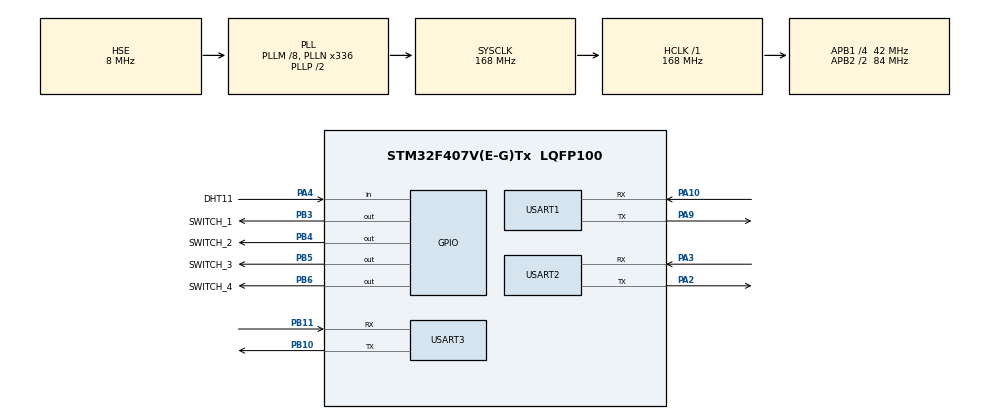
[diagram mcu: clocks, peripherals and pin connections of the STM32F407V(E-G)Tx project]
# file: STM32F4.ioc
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Dma.Request0=USART3_RX
Dma.Request1=USART3_TX
Dma.USART3_RX.0.Direction=DMA_PERIPH_TO_MEMORY
Dma.USART3_RX.0.FIFOMode=DMA_FIFOMODE_DISABLE
Dma.USART3_RX.0.Instance=DMA1_Stream1
Dma.USART3_RX.0.MemDataAlignment=DMA_MDATAALIGN_BYTE
Dma.USART3_RX.0.MemInc=DMA_MINC_ENABLE
Dma.USART3_RX.0.Mode=DMA_CIRCULAR
Dma.USART3_RX.0.PeriphDataAlignment=DMA_PDATAALIGN_BYTE
Dma.USART3_RX.0.PeriphInc=DMA_PINC_DISABLE
Dma.USART3_RX.0.Priority=DMA_PRIORITY_LOW
Dma.USART3_TX.1.Direction=DMA_MEMORY_TO_PERIPH
Dma.USART3_TX.1.FIFOMode=DMA_FIFOMODE_DISABLE
Dma.USART3_TX.1.Instance=DMA1_Stream3
Dma.USART3_TX.1.MemDataAlignment=DMA_MDATAALIGN_BYTE
Dma.USART3_TX.1.MemInc=DMA_MINC_ENABLE
Dma.USART3_TX.1.Mode=DMA_NORMAL
Dma.USART3_TX.1.PeriphDataAlignment=DMA_PDATAALIGN_BYTE
Dma.USART3_TX.1.PeriphInc=DMA_PINC_DISABLE
Dma.USART3_TX.1.Priority=DMA_PRIORITY_LOW
FREERTOS.Tasks01=defaultTask,24,128,StartDefaultTask,Default,NULL,Dynamic,NULL,NULL
Mcu.Family=STM32F4
Mcu.Name=STM32F407V(E-G)Tx
Mcu.Package=LQFP100
NVIC.DMA1_Stream1_IRQn=true\:5\:0\:false\:false\:true\:true\:false\:true\:true
NVIC.DMA1_Stream3_IRQn=true\:5\:0\:false\:false\:true\:true\:false\:true\:true
NVIC.PriorityGroup=NVIC_PRIORITYGROUP_4
NVIC.USART1_IRQn=true\:5\:0\:false\:false\:true\:true\:true\:true\:true
NVIC.USART3_IRQn=true\:5\:0\:false\:false\:true\:true\:true\:true\:true
PA10.Mode=Asynchronous
PA10.Signal=USART1_RX
PA13.Mode=Serial_Wire
PA13.Signal=SYS_JTMS-SWDIO
PA14.Mode=Serial_Wire
PA14.Signal=SYS_JTCK-SWCLK
PA2.Mode=Asynchronous
PA2.Signal=USART2_TX
PA3.Mode=Asynchronous
PA3.Signal=USART2_RX
PA4.GPIO_Label=DHT11
PA4.Signal=GPIO_Input
PA9.Mode=Asynchronous
PA9.Signal=USART1_TX
PB10.Mode=Asynchronous
PB10.Signal=USART3_TX
PB11.GPIO_PuPd=GPIO_NOPULL
PB11.Mode=Asynchronous
PB11.Signal=USART3_RX
PB3.GPIO_Label=SWITCH_1
PB3.Signal=GPIO_Output
PB4.GPIO_Label=SWITCH_2
PB4.Signal=GPIO_Output
PB5.GPIO_Label=SWITCH_3
PB5.Signal=GPIO_Output
PB6.GPIO_Label=SWITCH_4
PB6.Signal=GPIO_Output
PH0-OSC_IN.Mode=HSE-External-Oscillator
PH0-OSC_IN.Signal=RCC_OSC_IN
PH1-OSC_OUT.Mode=HSE-External-Oscillator
PH1-OSC_OUT.Signal=RCC_OSC_OUT
ProjectManager.HeapSize=0x200
ProjectManager.StackSize=0x400
ProjectManager.TargetToolchain=CMake
RCC.48MHZClocksFreq_Value=84000000
RCC.AHBFreq_Value=168000000
RCC.APB1CLKDivider=RCC_HCLK_DIV4
RCC.APB1Freq_Value=42000000
RCC.APB1TimFreq_Value=84000000
RCC.APB2CLKDivider=RCC_HCLK_DIV2
RCC.APB2Freq_Value=84000000
RCC.APB2TimFreq_Value=168000000
RCC.CortexFreq_Value=168000000
RCC.HCLKFreq_Value=168000000
RCC.HSE_VALUE=8000000
RCC.HSI_VALUE=16000000
RCC.LSE_VALUE=32768
RCC.PLLM=8
RCC.PLLMUL=RCC_PLL_MUL9
RCC.PLLN=336
RCC.PLLSourceVirtual=RCC_PLLSOURCE_HSE
RCC.SYSCLKFreq_VALUE=168000000
RCC.SYSCLKSource=RCC_SYSCLKSOURCE_PLLCLK
RCC.USBFreq_Value=72000000
RCC.VCOOutputFreq_Value=336000000
TIM2.Period=65535-1
TIM2.Prescaler=72-1
USART1.VirtualMode=VM_ASYNC
USART2.VirtualMode=VM_ASYNC
USART3.VirtualMode=VM_ASYNC
VP_FREERTOS_VS_CMSIS_V2.Mode=CMSIS_V2
VP_TIM2_VS_ClockSourceINT.Mode=Internal
VP_TIM3_VS_ClockSourceINT.Mode=Internal
board=custom

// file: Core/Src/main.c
/* USER CODE BEGIN Header */
/**
  ******************************************************************************
  * @file           : main.c
  * @brief          : Main program body
  ******************************************************************************
  * @attention
  *
  * Copyright (c) 2026 STMicroelectronics.
  * All rights reserved.
  *
  * This software is licensed under terms that can be found in the LICENSE file
  * in the root directory of this software component.
  * If no LICENSE file comes with this software, it is provided AS-IS.
  *
  ******************************************************************************
  */
/* USER CODE END Header */
#include "main.h"
#include "cmsis_os.h"

/* USER CODE BEGIN Includes */
#include "stdio.h"
#include "memory_monitor.h"
/* USER CODE END Includes */

TIM_HandleTypeDef htim2;
TIM_HandleTypeDef htim3;

UART_HandleTypeDef huart1;
UART_HandleTypeDef huart2;
UART_HandleTypeDef huart3;
DMA_HandleTypeDef hdma_usart3_rx;
DMA_HandleTypeDef hdma_usart3_tx;

/* Definitions for defaultTask */
osThreadId_t defaultTaskHandle;
const osThreadAttr_t defaultTask_attributes = {
  .name = "defaultTask",
  .stack_size = 128 * 4,
  .priority = (osPriority_t) osPriorityNormal,
};

void SystemClock_Config(void);
static void MX_GPIO_Init(void);
static void MX_DMA_Init(void);
static void MX_TIM2_Init(void);
static void MX_TIM3_Init(void);
static void MX_USART1_UART_Init(void);
static void MX_USART2_UART_Init(void);
static void MX_USART3_UART_Init(void);
void StartDefaultTask(void *argument);

/* USER CODE BEGIN 0 */
extern void main_bridge(void);

int _write(int file, char *ptr, int len) {
  HAL_UART_Transmit(&huart3, (uint8_t *)ptr, len, HAL_MAX_DELAY);
  return len;
}
/* USER CODE END 0 */

int main(void)
{

  /* MCU Configuration--------------------------------------------------------*/

  /* Reset of all peripherals, Initializes the Flash interface and the Systick. */
  HAL_Init();

  /* Configure the system clock */
  SystemClock_Config();

  /* Initialize all configured peripherals */
  MX_GPIO_Init();
  MX_DMA_Init();
  MX_TIM2_Init();
  MX_TIM3_Init();
  MX_USART1_UART_Init();
  MX_USART2_UART_Init();
  MX_USART3_UART_Init();
  /* USER CODE BEGIN 2 */
  printf("采集板已启动...\r\n");
  /* USER CODE END 2 */

  /* Init scheduler */
  osKernelInitialize();

  /* Create the thread(s) */
  /* creation of defaultTask */
  defaultTaskHandle = osThreadNew(StartDefaultTask, NULL, &defaultTask_attributes);

  /* USER CODE BEGIN RTOS_THREADS */
  /* add threads, ... */
  CreateMemoryMonitorTask();
  main_bridge();
  /* USER CODE END RTOS_THREADS */

  /* Start scheduler */
  osKernelStart();

  /* We should never get here as control is now taken by the scheduler */

  /* Infinite loop */
  while (1)
  {

    /* USER CODE BEGIN 3 */
    printf("I AM OK STM32F4\r\n");
  }
  /* USER CODE END 3 */
}

void SystemClock_Config(void)
{
  RCC_OscInitTypeDef RCC_OscInitStruct = {0};
  RCC_ClkInitTypeDef RCC_ClkInitStruct = {0};

  /** Configure the main internal regulator output voltage
  */
  __HAL_RCC_PWR_CLK_ENABLE();
  __HAL_PWR_VOLTAGESCALING_CONFIG(PWR_REGULATOR_VOLTAGE_SCALE1);

  /** Initializes the RCC Oscillators according to the specified parameters
  * in the RCC_OscInitTypeDef structure.
  */
  RCC_OscInitStruct.OscillatorType = RCC_OSCILLATORTYPE_HSE;
  RCC_OscInitStruct.HSEState = RCC_HSE_ON;
  RCC_OscInitStruct.PLL.PLLState = RCC_PLL_ON;
  RCC_OscInitStruct.PLL.PLLSource = RCC_PLLSOURCE_HSE;
  RCC_OscInitStruct.PLL.PLLM = 8;
  RCC_OscInitStruct.PLL.PLLN = 336;
  RCC_OscInitStruct.PLL.PLLP = RCC_PLLP_DIV2;
  RCC_OscInitStruct.PLL.PLLQ = 4;
  if (HAL_RCC_OscConfig(&RCC_OscInitStruct) != HAL_OK)
  {
    Error_Handler();
  }

  /** Initializes the CPU, AHB and APB buses clocks
  */
  RCC_ClkInitStruct.ClockType = RCC_CLOCKTYPE_HCLK|RCC_CLOCKTYPE_SYSCLK
                              |RCC_CLOCKTYPE_PCLK1|RCC_CLOCKTYPE_PCLK2;
  RCC_ClkInitStruct.SYSCLKSource = RCC_SYSCLKSOURCE_PLLCLK;
  RCC_ClkInitStruct.AHBCLKDivider = RCC_SYSCLK_DIV1;
  RCC_ClkInitStruct.APB1CLKDivider = RCC_HCLK_DIV4;
  RCC_ClkInitStruct.APB2CLKDivider = RCC_HCLK_DIV2;

  if (HAL_RCC_ClockConfig(&RCC_ClkInitStruct, FLASH_LATENCY_5) != HAL_OK)
  {
    Error_Handler();
  }
}

static void MX_TIM2_Init(void)
{

  TIM_ClockConfigTypeDef sClockSourceConfig = {0};
  TIM_MasterConfigTypeDef sMasterConfig = {0};

  htim2.Instance = TIM2;
  htim2.Init.Prescaler = 72-1;
  htim2.Init.CounterMode = TIM_COUNTERMODE_UP;
  htim2.Init.Period = 65535-1;
  htim2.Init.ClockDivision = TIM_CLOCKDIVISION_DIV1;
  htim2.Init.AutoReloadPreload = TIM_AUTORELOAD_PRELOAD_DISABLE;
  if (HAL_TIM_Base_Init(&htim2) != HAL_OK)
  {
    Error_Handler();
  }
  sClockSourceConfig.ClockSource = TIM_CLOCKSOURCE_INTERNAL;
  if (HAL_TIM_ConfigClockSource(&htim2, &sClockSourceConfig) != HAL_OK)
  {
    Error_Handler();
  }
  sMasterConfig.MasterOutputTrigger = TIM_TRGO_RESET;
  sMasterConfig.MasterSlaveMode = TIM_MASTERSLAVEMODE_DISABLE;
  if (HAL_TIMEx_MasterConfigSynchronization(&htim2, &sMasterConfig) != HAL_OK)
  {
    Error_Handler();
  }

}

static void MX_TIM3_Init(void)
{

  TIM_ClockConfigTypeDef sClockSourceConfig = {0};
  TIM_MasterConfigTypeDef sMasterConfig = {0};

  htim3.Instance = TIM3;
  htim3.Init.Prescaler = 0;
  htim3.Init.CounterMode = TIM_COUNTERMODE_UP;
  htim3.Init.Period = 65535;
  htim3.Init.ClockDivision = TIM_CLOCKDIVISION_DIV1;
  htim3.Init.AutoReloadPreload = TIM_AUTORELOAD_PRELOAD_DISABLE;
  if (HAL_TIM_Base_Init(&htim3) != HAL_OK)
  {
    Error_Handler();
  }
  sClockSourceConfig.ClockSource = TIM_CLOCKSOURCE_INTERNAL;
  if (HAL_TIM_ConfigClockSource(&htim3, &sClockSourceConfig) != HAL_OK)
  {
    Error_Handler();
  }
  sMasterConfig.MasterOutputTrigger = TIM_TRGO_RESET;
  sMasterConfig.MasterSlaveMode = TIM_MASTERSLAVEMODE_DISABLE;
  if (HAL_TIMEx_MasterConfigSynchronization(&htim3, &sMasterConfig) != HAL_OK)
  {
    Error_Handler();
  }

}

static void MX_USART1_UART_Init(void)
{

  huart1.Instance = USART1;
  huart1.Init.BaudRate = 115200;
  huart1.Init.WordLength = UART_WORDLENGTH_8B;
  huart1.Init.StopBits = UART_STOPBITS_1;
  huart1.Init.Parity = UART_PARITY_NONE;
  huart1.Init.Mode = UART_MODE_TX_RX;
  huart1.Init.HwFlowCtl = UART_HWCONTROL_NONE;
  huart1.Init.OverSampling = UART_OVERSAMPLING_16;
  if (HAL_UART_Init(&huart1) != HAL_OK)
  {
    Error_Handler();
  }

}

static void MX_USART2_UART_Init(void)
{

  huart2.Instance = USART2;
  huart2.Init.BaudRate = 115200;
  huart2.Init.WordLength = UART_WORDLENGTH_8B;
  huart2.Init.StopBits = UART_STOPBITS_1;
  huart2.Init.Parity = UART_PARITY_NONE;
  huart2.Init.Mode = UART_MODE_TX_RX;
  huart2.Init.HwFlowCtl = UART_HWCONTROL_NONE;
  huart2.Init.OverSampling = UART_OVERSAMPLING_16;
  if (HAL_UART_Init(&huart2) != HAL_OK)
  {
    Error_Handler();
  }

}

static void MX_USART3_UART_Init(void)
{

  huart3.Instance = USART3;
  huart3.Init.BaudRate = 115200;
  huart3.Init.WordLength = UART_WORDLENGTH_8B;
  huart3.Init.StopBits = UART_STOPBITS_1;
  huart3.Init.Parity = UART_PARITY_NONE;
  huart3.Init.Mode = UART_MODE_TX_RX;
  huart3.Init.HwFlowCtl = UART_HWCONTROL_NONE;
  huart3.Init.OverSampling = UART_OVERSAMPLING_16;
  if (HAL_UART_Init(&huart3) != HAL_OK)
  {
    Error_Handler();
  }

}

static void MX_DMA_Init(void)
{

  /* DMA controller clock enable */
  __HAL_RCC_DMA1_CLK_ENABLE();

  /* DMA interrupt init */
  /* DMA1_Stream1_IRQn interrupt configuration */
  HAL_NVIC_SetPriority(DMA1_Stream1_IRQn, 5, 0);
  HAL_NVIC_EnableIRQ(DMA1_Stream1_IRQn);
  /* DMA1_Stream3_IRQn interrupt configuration */
  HAL_NVIC_SetPriority(DMA1_Stream3_IRQn, 5, 0);
  HAL_NVIC_EnableIRQ(DMA1_Stream3_IRQn);

}

static void MX_GPIO_Init(void)
{
  GPIO_InitTypeDef GPIO_InitStruct = {0};

  /* GPIO Ports Clock Enable */
  __HAL_RCC_GPIOH_CLK_ENABLE();
  __HAL_RCC_GPIOA_CLK_ENABLE();
  __HAL_RCC_GPIOB_CLK_ENABLE();

  /*Configure GPIO pin Output Level */
  HAL_GPIO_WritePin(GPIOB, SWITCH_1_Pin|SWITCH_2_Pin|SWITCH_3_Pin|SWITCH_4_Pin, GPIO_PIN_RESET);

  /*Configure GPIO pin : DHT11_Pin */
  GPIO_InitStruct.Pin = DHT11_Pin;
  GPIO_InitStruct.Mode = GPIO_MODE_INPUT;
  GPIO_InitStruct.Pull = GPIO_NOPULL;
  HAL_GPIO_Init(DHT11_GPIO_Port, &GPIO_InitStruct);

  /*Configure GPIO pins : SWITCH_1_Pin SWITCH_2_Pin SWITCH_3_Pin SWITCH_4_Pin */
  GPIO_InitStruct.Pin = SWITCH_1_Pin|SWITCH_2_Pin|SWITCH_3_Pin|SWITCH_4_Pin;
  GPIO_InitStruct.Mode = GPIO_MODE_OUTPUT_PP;
  GPIO_InitStruct.Pull = GPIO_NOPULL;
  GPIO_InitStruct.Speed = GPIO_SPEED_FREQ_LOW;
  HAL_GPIO_Init(GPIOB, &GPIO_InitStruct);

}

void StartDefaultTask(void *argument)
{
  for(;;)
  {
    osDelay(1);
  }
}

void Error_Handler(void)
{
  __disable_irq();
  while (1)
  {
  }
}
